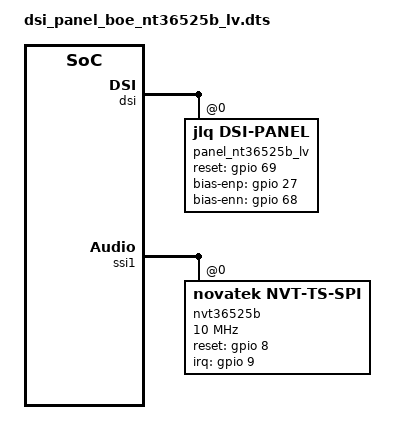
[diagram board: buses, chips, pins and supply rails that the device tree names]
// SPDX-License-Identifier: GPL-2.0+
/dts-v1/;
/plugin/;
#include <dt-bindings/pinctrl/jlq_pinctrl.h>
/ {
	jlq,panel-id   = <2 0>;
};

&dsi {
	panel_nt36525b_lv: nt36525b_lv {
		compatible = "jlq,dsi-panel";
		reg = <0>;
		panel_name = "xiaomi C3QP 35 02 0a hd+ video dsi panel";
		status = "okay";
		inited = "true";

		pinctrl-names = "panel_active", "panel_suspend";
		pinctrl-0 = <&lcd_reset_active
			&lcd_bias_enp_active
			&lcd_bias_enn_active>;
		pinctrl-1 = <&lcd_reset_suspend
			&lcd_bias_enp_suspend
			&lcd_bias_enn_suspend>;

		reset-gpio = <&gpio 69 0>;
		reset-sequence = <1 10 0 20 1 10>;
		reset-gpio-keep-high;
		bias-enp-gpio = <&gpio 27 0>;
		bias-enn-gpio = <&gpio 68 0>;

		dsi,lanes = <4>;
		dsi,channel = <0>;
		dsi,flags = <0x29400803>;
		dsi,format = <0>;

		init-delay-ms = <20>;
		prepare-delay-ms = <0>;
		enable-delay-ms = <2>;
		unprepare-delay-ms = <0>;
		disable-delay-ms = <2>;
		reset-delay-ms = <30>;
		width-mm = <68>;
		height-mm = <156>;
		backlight-type = <1>;
		backlight-max-level = <2047>;
		ic-vendor = <1>;
		cabc-support;
		hbm-support;
		hbm-percent = <80>;
                esd-check-mode = "reg_read";
                esd-check-period = <6000>;

		hbm-on-sequence = [
			29 01 02 ff 10
			29 00 02 fb 01
			29 00 03 51 07 d6
		];

		hbm-off-sequence = [
			29 01 02 ff 10
			29 00 02 fb 01
			29 00 03 51 06 65
		];

		mipi-pre-sequence = [
			29 01 02 ff 10
			29 00 02 fb 01
		];

		bl-off-pre-sequence = [
			29 00 02 53 24
		];

		panel-exit-sequence = [
			05 05 01 28
			05 78 01 10
		];

		panel-init-sequence = [
			//Gamma offset Related
			29 01 02 ff 20
			29 00 02 fb 01
			29 00 0d c3 27 26 1e 20 19 18 17 16 15 13 07 03

			29 01 02 ff 23
			29 00 02 fb 01
			29 00 02 00 68
			29 00 02 07 00
			29 00 02 08 01
			29 00 02 09 80

			//APL_WT = 0
			29 00 02 10 00

			//Resolution Related
			29 00 02 11 00
			29 00 02 12 90
			29 00 02 15 49
			29 00 02 16 09

			//GAMMA SEL
			29 00 02 19 00
			29 00 02 1a 00
			29 00 02 1b 08
			29 00 02 1c 0A
			29 00 02 1d 0C
			29 00 02 1e 12
			29 00 02 1f 16
			29 00 02 20 1A
			29 00 02 21 1C
			29 00 02 22 20
			29 00 02 23 24
			29 00 02 24 28
			29 00 02 25 2C
			29 00 02 26 30
			29 00 02 27 38
			29 00 02 28 3C
			29 00 02 29 10
			29 00 02 2a 20
			29 00 02 2b 20

			//PWM Related : UI Mode
			29 00 02 30 ff
			29 00 02 31 fe
			29 00 02 32 fd
			29 00 02 33 fc
			29 00 02 34 fb
			29 00 02 35 fa
			29 00 02 36 f9
			29 00 02 37 f8
			29 00 02 38 f7
			29 00 02 39 f6
			29 00 02 3a f5
			29 00 02 3b f4
			29 00 02 3d f3
			29 00 02 3f f2
			29 00 02 40 f1
			29 00 02 41 f0

			//PWM Related : Still Mode
			29 00 02 45 fe
			29 00 02 46 fe
			29 00 02 47 fd
			29 00 02 48 fb
			29 00 02 49 f9
			29 00 02 4a f6
			29 00 02 4b f2
			29 00 02 4c ed
			29 00 02 4d e7
			29 00 02 4e e0
			29 00 02 4f d8
			29 00 02 50 ce
			29 00 02 51 c2
			29 00 02 52 b4
			29 00 02 53 a4
			29 00 02 54 94

			//PWM Related : Mov Mode
			29 00 02 58 ff
			29 00 02 59 fe
			29 00 02 5a fc
			29 00 02 5b f9
			29 00 02 5c f5
			29 00 02 5d f1
			29 00 02 5e ed
			29 00 02 5f e8
			29 00 02 60 e2
			29 00 02 61 dc
			29 00 02 62 d6
			29 00 02 63 cf
			29 00 02 64 c7
			29 00 02 65 be
			29 00 02 66 ae
			29 00 02 67 9e

			29 01 02 ff 10
			29 00 02 fb 01
			29 00 02 51 00
			29 00 02 53 2c
			29 00 02 55 01
			29 00 03 68 03 01
			29 00 02 ba 03
			05 64 01 11
			05 32 01 29
		];

		lockdown-entries {
			#address-cells = <1>;
			#size-cells = <0>;

			lockdown-entry@0 {
				reg = <0>;
				return-packet-size = <1>;
				read-sequence = [
					29 01 02 ff 25
					29 01 02 fb 01
					06 01 01 d9
				];
			};

			lockdown-entry@1 {
				reg = <1>;
				return-packet-size = <1>;
				read-sequence = [
					29 01 02 ff 25
					29 01 02 fb 01
					06 01 01 da
				];
			};

			lockdown-entry@2 {
				reg = <2>;
				return-packet-size = <1>;
				read-sequence = [
					29 01 02 ff 25
					29 01 02 fb 01
					06 01 01 db
				];
			};

			lockdown-entry@3 {
				reg = <3>;
				return-packet-size = <1>;
				read-sequence = [
					29 01 02 ff 25
					29 01 02 fb 01
					06 01 01 dc
				];
			};

			lockdown-entry@4 {
				reg = <4>;
				return-packet-size = <1>;
				read-sequence = [
					29 01 02 ff 25
					29 01 02 fb 01
					06 01 01 dd
				];
			};

			lockdown-entry@5 {
				reg = <5>;
				return-packet-size = <1>;
				read-sequence = [
					29 01 02 ff 25
					29 01 02 fb 01
					06 01 01 f0
				];
			};

			lockdown-entry@6 {
				reg = <6>;
				return-packet-size = <1>;
				read-sequence = [
					29 01 02 ff 25
					29 01 02 fb 01
					06 01 01 f1
				];
			};

			lockdown-entry@7 {
				reg = <7>;
				return-packet-size = <1>;
				read-sequence = [
					29 01 02 ff 25
					29 01 02 fb 01
					06 01 01 f2
				];
			};
		};

		whitepoint-entries {
			#address-cells = <1>;
			#size-cells = <0>;

			whitepoint-entry@0 {
				reg = <0>;
				return-packet-size = <1>;
				read-sequence = [
					29 01 02 ff 20
					29 01 02 fb 01
					06 01 01 23
				];
			};

			whitepoint-entry@1 {
				reg = <1>;
				return-packet-size = <1>;
				read-sequence = [
					29 01 02 ff 20
					29 01 02 fb 01
					06 01 01 24
				];
			};

			whitepoint-entry@2 {
				reg = <2>;
				return-packet-size = <1>;
				read-sequence = [
					29 01 02 ff 20
					29 01 02 fb 01
					06 01 01 25
				];
			};

			whitepoint-entry@3 {
				reg = <3>;
				return-packet-size = <1>;
				read-sequence = [
					29 01 02 ff 20
					29 01 02 fb 01
					06 01 01 26
				];
			};

			whitepoint-entry@4 {
				reg = <4>;
				return-packet-size = <1>;
				read-sequence = [
					29 01 02 ff 20
					29 01 02 fb 01
					06 01 01 27
				];
			};

			whitepoint-entry@5 {
				reg = <5>;
				return-packet-size = <1>;
				read-sequence = [
					29 01 02 ff 20
					29 01 02 fb 01
					06 01 01 28
				];
			};
		};

                esd-entries {
                       #address-cells = <1>;
                       #size-cells = <0>;

                       esd-entry@0 {
                               reg = <0>;
                               return-packet-size = <1>;
                               valid-value-array = /bits/ 8 <0x9c>;
                               read-sequence = [
                                       29 01 02 ff 10
                                       29 00 02 fb 01
                                       06 01 01 0a
                               ];
                       };
               };


		display-timings {
			native-mode = <&nt36525b_lv_timing>;
			nt36525b_lv_timing: timing0 {
				clock-frequency = <110000000>;
				hactive = <720>;
				vactive = <1650>;
				hfront-porch = <120>;
				hsync-len = <2>;
				hback-porch = <108>;
				vfront-porch = <16>;
				vsync-len = <18>;
				vback-porch = <252>;
				hsync-active = <1>;
				vsync-active = <1>;
			};
		};
	};
};

&ssi1 {
	nvt36525b@0 {
		reg = <0>;
		status = "okay";
		panel = <&panel_nt36525b_lv>;
		compatible = "novatek,NVT-ts-spi";
		novatek,reset-gpio = <&gpio 8 0>;
		novatek,irq-gpio = <&gpio 9 0>;
		novatek,longv-mode = <0x1>;
		novatek,swrst-n8-addr = <0x03F0FE>;
		novatek,spi-rd-fast-addr = <0x03F310>;
		novatek,resolution-width = /bits/ 16 <720>;
		novatek,resolution-height = /bits/ 16 <1650>;
		spi-max-frequency = <10000000>;
                usb-dev-extcons = "4-006b", "4-003b";

		/* MP */
		novatek,mp-support-dt;
		novatek-mp-criteria-5968@0 {
			#address-cells = <1>;
			#size-cells = <0>;
			compatible = "novatek-mp-criteria-5968";

			/* MP Config */
			IC_X_CFG_SIZE = <18>;
			IC_Y_CFG_SIZE = <32>;
			IC_KEY_CFG_SIZE = <4>;
			X_Channel = <18>;
			Y_Channel = <32>;
			AIN_X = <0 1 2 3 4 5 6 7 8 9 10 11 12 13 14 15 16 17>;
			AIN_Y = <0 1 2 3 4 5 6 7 8 9 10 11 12 13 14 15 16 17 18 19 20 21 22 23 24 25 26 27 28 29 30 31>;
			//AIN_X = <0 1 2 3 4 5 6 7 8 9 10 11 12 13 14 15 16 17 18 19 20 21 22 23 24 25 26 27 28 29 30 31>;
			//AIN_Y = <0 1 2 3 4 5 6 7 8 9 10 11 12 13 14 15 16 17 18 19 20 21 22 23 24 25 26 27 28 29 30 31 32 33 34 35 36 37 38 39 40 41 42 43 44 45 46 47 48 49>;
			AIN_KEY = <0 1 2 0xFF>;

			/* MP Criteria */
			PS_Config_Lmt_Short_Rawdata_P = <
				14008	14008	14008	14008	14008	14008	14008	14008	14008	14008	14008	14008	14008	14008	14008	14008	14008	14008
				14008	14008	14008	14008	14008	14008	14008	14008	14008	14008	14008	14008	14008	14008	14008	14008	14008	14008
				14008	14008	14008	14008	14008	14008	14008	14008	14008	14008	14008	14008	14008	14008	14008	14008	14008	14008
				14008	14008	14008	14008	14008	14008	14008	14008	14008	14008	14008	14008	14008	14008	14008	14008	14008	14008
				14008	14008	14008	14008	14008	14008	14008	14008	14008	14008	14008	14008	14008	14008	14008	14008	14008	14008
				14008	14008	14008	14008	14008	14008	14008	14008	14008	14008	14008	14008	14008	14008	14008	14008	14008	14008
				14008	14008	14008	14008	14008	14008	14008	14008	14008	14008	14008	14008	14008	14008	14008	14008	14008	14008
				14008	14008	14008	14008	14008	14008	14008	14008	14008	14008	14008	14008	14008	14008	14008	14008	14008	14008
				14008	14008	14008	14008	14008	14008	14008	14008	14008	14008	14008	14008	14008	14008	14008	14008	14008	14008
				14008	14008	14008	14008	14008	14008	14008	14008	14008	14008	14008	14008	14008	14008	14008	14008	14008	14008
				14008	14008	14008	14008	14008	14008	14008	14008	14008	14008	14008	14008	14008	14008	14008	14008	14008	14008
				14008	14008	14008	14008	14008	14008	14008	14008	14008	14008	14008	14008	14008	14008	14008	14008	14008	14008
				14008	14008	14008	14008	14008	14008	14008	14008	14008	14008	14008	14008	14008	14008	14008	14008	14008	14008
				14008	14008	14008	14008	14008	14008	14008	14008	14008	14008	14008	14008	14008	14008	14008	14008	14008	14008
				14008	14008	14008	14008	14008	14008	14008	14008	14008	14008	14008	14008	14008	14008	14008	14008	14008	14008
				14008	14008	14008	14008	14008	14008	14008	14008	14008	14008	14008	14008	14008	14008	14008	14008	14008	14008
				14008	14008	14008	14008	14008	14008	14008	14008	14008	14008	14008	14008	14008	14008	14008	14008	14008	14008
				14008	14008	14008	14008	14008	14008	14008	14008	14008	14008	14008	14008	14008	14008	14008	14008	14008	14008
				14008	14008	14008	14008	14008	14008	14008	14008	14008	14008	14008	14008	14008	14008	14008	14008	14008	14008
				14008	14008	14008	14008	14008	14008	14008	14008	14008	14008	14008	14008	14008	14008	14008	14008	14008	14008
				14008	14008	14008	14008	14008	14008	14008	14008	14008	14008	14008	14008	14008	14008	14008	14008	14008	14008
				14008	14008	14008	14008	14008	14008	14008	14008	14008	14008	14008	14008	14008	14008	14008	14008	14008	14008
				14008	14008	14008	14008	14008	14008	14008	14008	14008	14008	14008	14008	14008	14008	14008	14008	14008	14008
				14008	14008	14008	14008	14008	14008	14008	14008	14008	14008	14008	14008	14008	14008	14008	14008	14008	14008
				14008	14008	14008	14008	14008	14008	14008	14008	14008	14008	14008	14008	14008	14008	14008	14008	14008	14008
				14008	14008	14008	14008	14008	14008	14008	14008	14008	14008	14008	14008	14008	14008	14008	14008	14008	14008
				14008	14008	14008	14008	14008	14008	14008	14008	14008	14008	14008	14008	14008	14008	14008	14008	14008	14008
				14008	14008	14008	14008	14008	14008	14008	14008	14008	14008	14008	14008	14008	14008	14008	14008	14008	14008
				14008	14008	14008	14008	14008	14008	14008	14008	14008	14008	14008	14008	14008	14008	14008	14008	14008	14008
				14008	14008	14008	14008	14008	14008	14008	14008	14008	14008	14008	14008	14008	14008	14008	14008	14008	14008
				14008	14008	14008	14008	14008	14008	14008	14008	14008	14008	14008	14008	14008	14008	14008	14008	14008	14008
				14008	14008	14008	14008	14008	14008	14008	14008	14008	14008	14008	14008	14008	14008	14008	14008	14008	14008>;

			PS_Config_Lmt_Short_Rawdata_N = <
				11376	11376	11376	11376	11376	11376	11376	11376	11376	11376	11376	11376	11376	11376	11376	11376	11376	11376
				11376	11376	11376	11376	11376	11376	11376	11376	11376	11376	11376	11376	11376	11376	11376	11376	11376	11376
				11376	11376	11376	11376	11376	11376	11376	11376	11376	11376	11376	11376	11376	11376	11376	11376	11376	11376
				11376	11376	11376	11376	11376	11376	11376	11376	11376	11376	11376	11376	11376	11376	11376	11376	11376	11376
				11376	11376	11376	11376	11376	11376	11376	11376	11376	11376	11376	11376	11376	11376	11376	11376	11376	11376
				11376	11376	11376	11376	11376	11376	11376	11376	11376	11376	11376	11376	11376	11376	11376	11376	11376	11376
				11376	11376	11376	11376	11376	11376	11376	11376	11376	11376	11376	11376	11376	11376	11376	11376	11376	11376
				11376	11376	11376	11376	11376	11376	11376	11376	11376	11376	11376	11376	11376	11376	11376	11376	11376	11376
				11376	11376	11376	11376	11376	11376	11376	11376	11376	11376	11376	11376	11376	11376	11376	11376	11376	11376
				11376	11376	11376	11376	11376	11376	11376	11376	11376	11376	11376	11376	11376	11376	11376	11376	11376	11376
				11376	11376	11376	11376	11376	11376	11376	11376	11376	11376	11376	11376	11376	11376	11376	11376	11376	11376
				11376	11376	11376	11376	11376	11376	11376	11376	11376	11376	11376	11376	11376	11376	11376	11376	11376	11376
				11376	11376	11376	11376	11376	11376	11376	11376	11376	11376	11376	11376	11376	11376	11376	11376	11376	11376
				11376	11376	11376	11376	11376	11376	11376	11376	11376	11376	11376	11376	11376	11376	11376	11376	11376	11376
				11376	11376	11376	11376	11376	11376	11376	11376	11376	11376	11376	11376	11376	11376	11376	11376	11376	11376
				11376	11376	11376	11376	11376	11376	11376	11376	11376	11376	11376	11376	11376	11376	11376	11376	11376	11376
				11376	11376	11376	11376	11376	11376	11376	11376	11376	11376	11376	11376	11376	11376	11376	11376	11376	11376
				11376	11376	11376	11376	11376	11376	11376	11376	11376	11376	11376	11376	11376	11376	11376	11376	11376	11376
				11376	11376	11376	11376	11376	11376	11376	11376	11376	11376	11376	11376	11376	11376	11376	11376	11376	11376
				11376	11376	11376	11376	11376	11376	11376	11376	11376	11376	11376	11376	11376	11376	11376	11376	11376	11376
				11376	11376	11376	11376	11376	11376	11376	11376	11376	11376	11376	11376	11376	11376	11376	11376	11376	11376
				11376	11376	11376	11376	11376	11376	11376	11376	11376	11376	11376	11376	11376	11376	11376	11376	11376	11376
				11376	11376	11376	11376	11376	11376	11376	11376	11376	11376	11376	11376	11376	11376	11376	11376	11376	11376
				11376	11376	11376	11376	11376	11376	11376	11376	11376	11376	11376	11376	11376	11376	11376	11376	11376	11376
				11376	11376	11376	11376	11376	11376	11376	11376	11376	11376	11376	11376	11376	11376	11376	11376	11376	11376
				11376	11376	11376	11376	11376	11376	11376	11376	11376	11376	11376	11376	11376	11376	11376	11376	11376	11376
				11376	11376	11376	11376	11376	11376	11376	11376	11376	11376	11376	11376	11376	11376	11376	11376	11376	11376
				11376	11376	11376	11376	11376	11376	11376	11376	11376	11376	11376	11376	11376	11376	11376	11376	11376	11376
				11376	11376	11376	11376	11376	11376	11376	11376	11376	11376	11376	11376	11376	11376	11376	11376	11376	11376
				11376	11376	11376	11376	11376	11376	11376	11376	11376	11376	11376	11376	11376	11376	11376	11376	11376	11376
				11376	11376	11376	11376	11376	11376	11376	11376	11376	11376	11376	11376	11376	11376	11376	11376	11376	11376
				11376	11376	11376	11376	11376	11376	11376	11376	11376	11376	11376	11376	11376	11376	11376	11376	11376	11376>;

			PS_Config_Lmt_Open_Rawdata_P = <
				3376	3326	3341	3410	3444	3432	3330	3455	65535	65535	3379	3256	3364	3376	3395	3382	3381	3406
				3133	3151	3185	3232	3273	3274	3264	3257	3232	3213	3256	3260	3280	3280	3294	3301	3277	3225
				3187	3207	3238	3288	3333	3334	3322	3319	3283	3186	3229	3236	3250	3253	3263	3274	3253	3213
				3164	3175	3207	3257	3304	3306	3292	3290	3252	3232	3281	3288	3302	3305	3313	3326	3309	3276
				3287	3306	3340	3395	3449	3449	3434	3434	3390	3281	3334	3341	3355	3362	3369	3381	3361	3325
				3276	3290	3325	3382	3432	3446	3432	3428	3385	3333	3390	3399	3413	3420	3425	3435	3424	3390
				3339	3357	3381	3395	3397	3396	3404	3400	3365	3466	3483	3493	3484	3476	3416	3344	3297	3257
				3421	3437	3463	3479	3476	3477	3477	3473	3437	3504	3519	3526	3526	3522	3472	3400	3353	3312
				3383	3402	3428	3449	3446	3448	3444	3446	3409	3498	3516	3521	3526	3526	3476	3403	3361	3318
				3431	3448	3480	3495	3495	3497	3491	3484	3448	3554	3575	3586	3591	3593	3544	3473	3430	3386
				3493	3511	3544	3564	3558	3557	3556	3543	3519	3556	3571	3588	3593	3598	3558	3491	3449	3406
				3536	3553	3586	3605	3602	3600	3586	3577	3557	3607	3621	3635	3654	3658	3617	3547	3505	3458
				3518	3535	3585	3599	3598	3592	3581	3574	3564	3610	3624	3631	3652	3658	3623	3560	3505	3456
				3563	3579	3630	3645	3637	3638	3623	3616	3605	3651	3665	3672	3693	3697	3668	3606	3549	3504
				3567	3586	3635	3645	3641	3637	3628	3626	3612	3630	3645	3654	3665	3672	3645	3599	3547	3502
				3599	3619	3663	3672	3663	3663	3651	3647	3630	3686	3701	3711	3725	3732	3715	3672	3616	3574
				3624	3641	3683	3689	3687	3682	3675	3668	3655	3696	3708	3722	3732	3740	3722	3686	3634	3589
				3673	3690	3731	3739	3735	3732	3721	3714	3697	3746	3763	3778	3789	3799	3787	3754	3707	3662
				3679	3691	3721	3728	3728	3722	3715	3704	3690	3722	3745	3756	3770	3780	3767	3735	3700	3654
				3742	3743	3775	3789	3787	3784	3778	3764	3747	3768	3788	3803	3817	3827	3826	3789	3752	3712
				3750	3747	3781	3794	3791	3785	3778	3768	3752	3747	3771	3785	3801	3809	3810	3777	3742	3705
				3785	3781	3813	3824	3820	3817	3810	3798	3781	3788	3812	3829	3844	3854	3861	3831	3795	3763
				3824	3822	3841	3866	3866	3861	3855	3845	3823	3795	3823	3837	3854	3865	3878	3868	3844	3817
				3810	3803	3820	3844	3844	3840	3830	3819	3801	3820	3843	3859	3876	3885	3900	3894	3873	3848
				3854	3840	3858	3878	3883	3878	3872	3859	3841	3795	3823	3837	3851	3862	3876	3876	3859	3841
				3831	3817	3833	3848	3854	3848	3841	3830	3812	3862	3886	3901	3915	3929	3941	3948	3932	3917
				3768	3875	3886	3901	3903	3901	3900	3889	3873	3848	3871	3885	3890	3906	3917	3925	3915	3781
				3624	3851	3859	3869	3872	3868	3866	3858	3841	3893	3914	3929	3938	3950	3964	3977	3970	3704
				3680	3785	3787	3791	3791	3788	3782	3773	3757	3739	3760	3771	3782	3796	3812	3827	3830	3696
				3518	3752	3750	3752	3752	3743	3739	3731	3717	3749	3767	3781	3791	3805	3819	3840	3843	3572
				3578	3819	3815	3813	3813	3806	3803	3794	3781	3736	3754	3767	3775	3789	3805	3826	3836	3567
				3626	3745	3795	3792	3792	3782	3778	3766	3746	3791	3815	3829	3840	3852	3868	3887	3840	3696>;

			PS_Config_Lmt_Open_Rawdata_N = <
				1447	1425	1432	1461	1476	1471	1427	1480	(-65535)	(-65535)	1448	1395	1441	1447	1455	1449	1449	1459
				1342	1350	1365	1385	1402	1403	1399	1396	1385	1377	1395	1397	1405	1405	1411	1414	1404	1382
				1366	1374	1387	1409	1428	1429	1423	1422	1407	1365	1384	1387	1393	1394	1398	1403	1394	1377
				1356	1360	1374	1396	1416	1417	1411	1410	1393	1385	1406	1409	1415	1416	1420	1425	1418	1404
				1408	1417	1431	1455	1478	1478	1471	1471	1453	1406	1429	1432	1438	1441	1444	1449	1440	1425
				1404	1410	1425	1449	1471	1477	1471	1469	1450	1428	1453	1456	1462	1465	1468	1472	1467	1453
				1431	1438	1449	1455	1456	1455	1459	1457	1442	1485	1492	1497	1493	1489	1464	1433	1413	1396
				1466	1473	1484	1491	1489	1490	1490	1488	1473	1501	1508	1511	1511	1509	1488	1457	1437	1419
				1450	1458	1469	1478	1477	1477	1476	1477	1461	1499	1507	1509	1511	1511	1489	1458	1440	1422
				1470	1477	1491	1498	1498	1498	1496	1493	1477	1523	1532	1537	1539	1540	1519	1488	1470	1451
				1497	1504	1519	1527	1525	1524	1524	1518	1508	1524	1530	1537	1540	1542	1525	1496	1478	1459
				1515	1522	1537	1545	1543	1543	1537	1533	1524	1546	1552	1558	1566	1567	1550	1520	1502	1482
				1507	1515	1536	1542	1542	1539	1534	1531	1527	1547	1553	1556	1565	1567	1552	1525	1502	1481
				1527	1534	1555	1562	1558	1559	1552	1549	1545	1564	1570	1573	1582	1584	1572	1545	1521	1501
				1528	1537	1558	1562	1560	1558	1555	1554	1548	1555	1562	1566	1570	1573	1562	1542	1520	1501
				1542	1551	1570	1573	1570	1570	1564	1563	1555	1579	1586	1590	1596	1599	1592	1573	1549	1531
				1553	1560	1578	1581	1580	1578	1575	1572	1566	1584	1589	1595	1599	1603	1595	1579	1557	1538
				1574	1581	1599	1602	1600	1599	1594	1591	1584	1605	1612	1619	1624	1628	1623	1609	1588	1569
				1576	1582	1594	1597	1597	1595	1592	1587	1581	1595	1605	1609	1615	1620	1614	1600	1585	1566
				1603	1604	1618	1624	1623	1621	1619	1613	1606	1615	1623	1630	1636	1640	1639	1624	1608	1591
				1607	1606	1620	1626	1624	1622	1619	1615	1608	1606	1616	1622	1629	1632	1633	1618	1603	1588
				1622	1620	1634	1639	1637	1636	1633	1627	1620	1623	1633	1641	1647	1651	1654	1642	1626	1612
				1639	1638	1646	1657	1657	1654	1652	1648	1638	1626	1638	1644	1651	1656	1662	1657	1647	1636
				1633	1630	1637	1647	1647	1645	1641	1636	1629	1637	1647	1654	1661	1665	1671	1669	1660	1649
				1651	1645	1653	1662	1664	1662	1659	1654	1646	1626	1638	1644	1650	1655	1661	1661	1654	1646
				1642	1636	1642	1649	1651	1649	1646	1641	1633	1655	1665	1672	1678	1684	1689	1692	1685	1678
				1615	1660	1665	1672	1672	1672	1671	1666	1660	1649	1659	1665	1667	1674	1678	1682	1678	1620
				1553	1650	1654	1658	1659	1657	1657	1653	1646	1668	1677	1684	1687	1693	1699	1704	1701	1587
				1577	1622	1623	1624	1624	1623	1621	1617	1610	1602	1611	1616	1621	1627	1633	1640	1641	1584
				1507	1608	1607	1608	1608	1604	1602	1599	1593	1606	1614	1620	1624	1630	1636	1645	1647	1531
				1533	1636	1635	1634	1634	1631	1630	1626	1620	1601	1609	1614	1618	1624	1630	1639	1644	1528
				1554	1605	1626	1625	1625	1621	1619	1614	1605	1624	1635	1641	1645	1651	1657	1666	1645	1584>;

			PS_Config_Lmt_FW_Rawdata_P = <
				2262	2228	2235	2217	2231	2233	2248	2242	65535	65535	2262	2252	2242	2226	2240	2231	2237	2244
				2238	2249	2266	2254	2259	2251	2252	2228	2245	2196	2227	2228	2241	2228	2226	2240	2238	2240
				2261	2244	2235	2251	2235	2240	2219	2238	2234	2247	2252	2262	2263	2255	2247	2268	2242	2220
				2249	2228	2237	2217	2233	2228	2233	2244	2241	2249	2214	2221	2221	2209	2209	2213	2255	2254
				2255	2242	2231	2237	2247	2258	2245	2254	2247	2263	2258	2258	2256	2227	2238	2245	2219	2265
				2261	2233	2231	2249	2231	2234	2242	2248	2247	2245	2256	2245	2238	2258	2244	2258	2248	2217
				2249	2245	2235	2234	2242	2265	2219	2235	2227	2256	2221	2237	2221	2265	2242	2226	2247	2249
				2251	2240	2263	2242	2240	2233	2238	2248	2241	2228	2254	2251	2228	2226	2242	2255	2240	2238
				2227	2233	2262	2226	2251	2235	2234	2235	2251	2219	2213	2245	2235	2221	2268	2244	2258	2256
				2248	2245	2223	2224	2224	2241	2224	2234	2231	2235	2233	2234	2228	2200	2252	2263	2242	2235
				2227	2242	2240	2241	2247	2248	2240	2221	2235	2251	2242	2235	2235	2219	2242	2248	2258	2245
				2265	2256	2251	2248	2251	2255	2268	2259	2254	2214	2255	2262	2258	2235	2219	2241	2223	2248
				2230	2259	2247	2256	2249	2251	2249	2256	2242	2265	2228	2242	2242	2248	2259	2235	2230	2245
				2206	2272	2254	2251	2252	2249	2259	2261	2263	2234	2275	2262	2268	2240	2230	2227	2245	2242
				2248	2231	2224	2220	2249	2252	2266	2234	2244	2255	2230	2240	2244	2244	2255	2227	2234	2237
				2221	2255	2259	2251	2249	2252	2255	2251	2235	2252	2227	2224	2226	2242	2252	2244	2224	2235
				2221	2238	2256	2237	2252	2240	2241	2210	2219	2210	2231	2235	2241	2224	2219	2259	2230	2247
				2263	2207	2203	2216	2230	2265	2249	2230	2234	2240	2233	2241	2237	2249	2242	2261	2244	2241
				2212	2217	2207	2216	2200	2198	2207	2223	2212	2224	2273	2248	2214	2269	2266	2219	2249	2244
				2234	2284	2258	2276	2252	2247	2261	2235	2258	2237	2268	2248	2251	2263	2270	2261	2233	2221
				2249	2247	2241	2269	2231	2227	2249	2235	2235	2270	2224	2230	2238	2254	2240	2238	2231	2251
				2251	2248	2240	2240	2259	2251	2252	2249	2252	2210	2227	2220	2230	2217	2223	2216	2234	2251
				2245	2259	2251	2259	2234	2247	2262	2238	2238	2224	2231	2235	2242	2214	2235	2226	2254	2221
				2254	2244	2235	2242	2234	2247	2249	2259	2240	2237	2234	2227	2238	2251	2221	2233	2247	2261
				2216	2251	2242	2249	2251	2228	2247	2252	2256	2248	2249	2249	2244	2268	2256	2251	2255	2265
				2233	2248	2224	2234	2223	2228	2226	2233	2228	2251	2217	2227	2220	2244	2251	2255	2240	2224
				2254	2251	2234	2240	2266	2254	2258	2255	2233	2262	2212	2217	2221	2220	2214	2228	2226	2258
				2254	2261	2279	2263	2268	2265	2265	2263	2258	2269	2210	2209	2220	2262	2256	2220	2228	2255
				2263	2223	2224	2235	2231	2248	2231	2228	2249	2254	2227	2249	2248	2254	2248	2256	2231	2227
				2244	2247	2230	2235	2214	2212	2213	2224	2226	2231	2214	2226	2230	2272	2220	2210	2226	2252
				2259	2231	2251	2242	2251	2251	2254	2237	2254	2233	2248	2254	2262	2255	2269	2273	2234	2233
				2228	2259	2238	2220	2226	2221	2228	2227	2245	2216	2206	2202	2205	2241	2240	2235	2252	2279>;

			PS_Config_Lmt_FW_Rawdata_N = <
				969	955	958	950	956	957	963	961	(-65535)	(-65535)	969	965	961	954	960	956	958	961
				959	964	971	966	968	964	965	955	962	941	954	955	960	955	954	960	959	960
				969	961	958	964	958	960	951	959	957	963	965	969	970	966	963	972	961	951
				964	955	958	950	957	955	957	961	960	964	949	952	952	946	946	948	966	966
				966	961	956	958	963	967	962	966	963	970	967	967	967	954	959	962	951	970
				969	957	956	964	956	957	961	963	963	962	967	962	959	967	961	967	963	950
				964	962	958	957	961	970	951	958	954	967	952	958	952	970	961	954	963	964
				964	960	970	961	960	957	959	963	960	955	966	964	955	954	961	966	960	959
				954	957	969	954	964	958	957	958	964	951	948	962	958	952	972	961	967	967
				963	962	952	953	953	960	953	957	956	958	957	957	955	943	965	970	961	958
				954	961	960	960	963	963	960	952	958	964	961	958	958	951	961	963	967	962
				970	967	964	963	964	966	972	968	966	949	966	969	967	958	951	960	952	963
				955	968	963	967	964	964	964	967	961	970	955	961	961	963	968	958	955	962
				945	973	966	964	965	964	968	969	970	957	975	969	972	960	955	954	962	961
				963	956	953	951	964	965	971	957	961	966	955	960	961	961	966	954	957	958
				952	966	968	964	964	965	966	964	958	965	954	953	954	961	965	961	953	958
				952	959	967	958	965	960	960	947	951	947	956	958	960	953	951	968	955	963
				970	946	944	949	955	970	964	955	957	960	957	960	958	964	961	969	961	960
				948	950	946	949	943	942	946	952	948	953	974	963	949	972	971	951	964	961
				957	979	967	975	965	963	969	958	967	958	972	963	964	970	973	969	957	952
				964	963	960	972	956	954	964	958	958	973	953	955	959	966	960	959	956	964
				964	963	960	960	968	964	965	964	965	947	954	951	955	950	952	949	957	964
				962	968	964	968	957	963	969	959	959	953	956	958	961	949	958	954	966	952
				966	961	958	961	957	963	964	968	960	958	957	954	959	964	952	957	963	969
				949	964	961	964	964	955	963	965	967	963	964	964	961	972	967	964	966	970
				957	963	953	957	952	955	954	957	955	964	950	954	951	961	964	966	960	953
				966	964	957	960	971	966	967	966	957	969	948	950	952	951	949	955	954	967
				966	969	976	970	972	970	970	970	967	972	947	946	951	969	967	951	955	966
				970	952	953	958	956	963	956	955	964	966	954	964	963	966	963	967	956	954
				961	963	955	958	949	948	948	953	954	956	949	954	955	973	951	947	954	965
				968	956	964	961	964	964	966	958	966	957	963	966	969	966	972	974	957	957
				955	968	959	951	954	952	955	954	962	949	945	943	945	960	960	958	965	976>;

			PS_Config_Lmt_FW_CC_P = <
				91	91	91	92	92	92	92	92	65535	65535	96	96	96	95	95	95	93	95
				95	93	93	93	93	93	93	93	96	99	96	96	96	96	96	96	97	99
				95	93	93	93	93	93	93	93	96	99	97	96	97	96	96	97	97	99
				95	93	92	93	93	93	93	95	96	99	97	97	97	97	97	97	97	99
				96	95	93	95	95	95	95	95	97	99	96	96	97	96	96	97	97	99
				96	95	95	95	96	96	96	96	99	100	99	99	99	97	97	99	99	100
				96	95	95	95	95	93	95	95	97	103	100	100	100	99	99	99	99	100
				100	99	99	99	99	99	99	99	102	106	103	103	103	103	102	102	102	103
				97	96	95	95	95	95	95	95	97	103	100	100	100	100	99	99	99	100
				102	99	99	99	99	99	99	99	102	106	104	104	104	104	103	102	103	104
				97	96	95	95	95	95	95	96	97	102	100	100	100	99	99	99	99	100
				100	99	99	99	99	99	99	99	102	106	104	104	104	103	103	103	103	104
				97	96	96	96	96	95	96	96	99	103	100	100	100	100	100	99	99	102
				103	102	102	102	102	102	102	102	104	107	104	104	104	104	104	103	104	106
				97	96	96	96	96	96	96	96	99	103	102	102	102	102	100	100	100	102
				102	100	100	100	100	100	100	100	103	107	104	104	106	104	104	104	104	106
				99	96	96	96	96	96	96	96	99	104	102	102	102	102	102	100	102	103
				103	102	102	102	102	100	100	102	104	107	104	104	104	104	104	103	104	106
				99	97	96	97	96	96	96	96	99	103	102	102	102	100	100	100	102	103
				104	102	102	102	102	102	102	102	104	107	106	106	106	104	104	104	104	107
				100	97	97	97	97	97	97	97	100	103	102	102	102	102	102	102	102	103
				103	102	102	102	102	102	102	102	104	109	106	106	106	106	106	106	106	109
				100	97	97	97	97	97	97	97	100	104	102	102	102	102	102	102	102	104
				100	99	97	99	97	97	97	99	100	104	102	102	102	102	102	102	103	104
				100	97	97	97	97	97	97	97	100	106	103	103	103	103	103	103	103	106
				102	100	100	100	100	100	100	100	103	104	103	103	103	102	102	102	103	106
				100	99	99	99	99	99	99	99	102	104	103	103	103	103	103	103	103	104
				100	100	99	100	99	99	99	100	102	106	103	103	103	103	103	103	104	104
				99	99	97	97	97	97	97	97	100	104	103	103	103	102	103	103	103	104
				99	99	99	99	99	99	99	99	102	103	102	102	102	100	102	102	102	102
				97	97	97	97	97	97	97	97	100	103	100	100	100	100	100	100	102	102
				100	99	99	99	99	99	99	99	102	106	102	103	103	102	102	102	103	103>;

			PS_Config_Lmt_FW_CC_N = <
				40	40	40	41	41	41	41	41	(-65535)	(-65535)	43	43	43	42	42	42	42	42
				42	42	42	42	42	42	42	42	43	44	43	43	43	43	43	43	44	44
				42	42	42	42	42	42	42	42	43	44	44	43	44	43	43	44	44	44
				42	42	41	42	42	42	42	42	43	44	44	44	44	44	44	44	44	44
				43	42	42	42	42	42	42	42	44	44	43	43	44	43	43	44	44	44
				43	42	42	42	43	43	43	43	44	45	44	44	44	44	44	44	44	45
				43	42	42	42	42	42	42	42	44	46	45	45	45	44	44	44	44	45
				45	44	44	44	44	44	44	44	45	47	46	46	46	46	45	45	45	46
				44	43	42	42	42	42	42	42	44	46	45	45	45	45	44	44	44	45
				45	44	44	44	44	44	44	44	45	47	47	47	47	47	46	45	46	47
				44	43	42	42	42	42	42	43	44	45	45	45	45	44	44	44	44	45
				45	44	44	44	44	44	44	44	45	47	47	47	47	46	46	46	46	47
				44	43	43	43	43	42	43	43	44	46	45	45	45	45	45	44	44	45
				46	45	45	45	45	45	45	45	47	48	47	47	47	47	47	46	47	47
				44	43	43	43	43	43	43	43	44	46	45	45	45	45	45	45	45	45
				45	45	45	45	45	45	45	45	46	48	47	47	47	47	47	47	47	47
				44	43	43	43	43	43	43	43	44	47	45	45	45	45	45	45	45	46
				46	45	45	45	45	45	45	45	47	48	47	47	47	47	47	46	47	47
				44	44	43	44	43	43	43	43	44	46	45	45	45	45	45	45	45	46
				47	45	45	45	45	45	45	45	47	48	47	47	47	47	47	47	47	48
				45	44	44	44	44	44	44	44	45	46	45	45	45	45	45	45	45	46
				46	45	45	45	45	45	45	45	47	48	47	47	47	47	47	47	47	48
				45	44	44	44	44	44	44	44	45	47	45	45	45	45	45	45	45	47
				45	44	44	44	44	44	44	44	45	47	45	45	45	45	45	45	46	47
				45	44	44	44	44	44	44	44	45	47	46	46	46	46	46	46	46	47
				45	45	45	45	45	45	45	45	46	47	46	46	46	45	45	45	46	47
				45	44	44	44	44	44	44	44	45	47	46	46	46	46	46	46	46	47
				45	45	44	45	44	44	44	45	45	47	46	46	46	46	46	46	47	47
				44	44	44	44	44	44	44	44	45	47	46	46	46	45	46	46	46	47
				44	44	44	44	44	44	44	44	45	46	45	45	45	45	45	45	45	45
				44	44	44	44	44	44	44	44	45	46	45	45	45	45	45	45	45	45
				45	44	44	44	44	44	44	44	45	47	45	46	46	45	45	45	46	46>;

			PS_Config_Lmt_FW_Diff_P = <
				50	50	50	50	50	50	50	50	65535	65535	50	50	50	50	50	50	50	50
				50	50	50	50	50	50	50	50	50	50	50	50	50	50	50	50	50	50
				50	50	50	50	50	50	50	50	50	50	50	50	50	50	50	50	50	50
				50	50	50	50	50	50	50	50	50	50	50	50	50	50	50	50	50	50
				50	50	50	50	50	50	50	50	50	50	50	50	50	50	50	50	50	50
				50	50	50	50	50	50	50	50	50	50	50	50	50	50	50	50	50	50
				50	50	50	50	50	50	50	50	50	50	50	50	50	50	50	50	50	50
				50	50	50	50	50	50	50	50	50	50	50	50	50	50	50	50	50	50
				50	50	50	50	50	50	50	50	50	50	50	50	50	50	50	50	50	50
				50	50	50	50	50	50	50	50	50	50	50	50	50	50	50	50	50	50
				50	50	50	50	50	50	50	50	50	50	50	50	50	50	50	50	50	50
				50	50	50	50	50	50	50	50	50	50	50	50	50	50	50	50	50	50
				50	50	50	50	50	50	50	50	50	50	50	50	50	50	50	50	50	50
				50	50	50	50	50	50	50	50	50	50	50	50	50	50	50	50	50	50
				50	50	50	50	50	50	50	50	50	50	50	50	50	50	50	50	50	50
				50	50	50	50	50	50	50	50	50	50	50	50	50	50	50	50	50	50
				50	50	50	50	50	50	50	50	50	50	50	50	50	50	50	50	50	50
				50	50	50	50	50	50	50	50	50	50	50	50	50	50	50	50	50	50
				50	50	50	50	50	50	50	50	50	50	50	50	50	50	50	50	50	50
				50	50	50	50	50	50	50	50	50	50	50	50	50	50	50	50	50	50
				50	50	50	50	50	50	50	50	50	50	50	50	50	50	50	50	50	50
				50	50	50	50	50	50	50	50	50	50	50	50	50	50	50	50	50	50
				50	50	50	50	50	50	50	50	50	50	50	50	50	50	50	50	50	50
				50	50	50	50	50	50	50	50	50	50	50	50	50	50	50	50	50	50
				50	50	50	50	50	50	50	50	50	50	50	50	50	50	50	50	50	50
				50	50	50	50	50	50	50	50	50	50	50	50	50	50	50	50	50	50
				50	50	50	50	50	50	50	50	50	50	50	50	50	50	50	50	50	50
				50	50	50	50	50	50	50	50	50	50	50	50	50	50	50	50	50	50
				50	50	50	50	50	50	50	50	50	50	50	50	50	50	50	50	50	50
				50	50	50	50	50	50	50	50	50	50	50	50	50	50	50	50	50	50
				50	50	50	50	50	50	50	50	50	50	50	50	50	50	50	50	50	50
				50	50	50	50	50	50	50	50	50	50	50	50	50	50	50	50	50	50>;

			PS_Config_Lmt_FW_Diff_N = <
				(-50)	(-50)	(-50)	(-50)	(-50)	(-50)	(-50)	(-50)	(-65535)	(-65535)	(-50)	(-50)	(-50)	(-50)	(-50)	(-50)	(-50)	(-50)
				(-50)	(-50)	(-50)	(-50)	(-50)	(-50)	(-50)	(-50)	(-50)	(-50)	(-50)	(-50)	(-50)	(-50)	(-50)	(-50)	(-50)	(-50)
				(-50)	(-50)	(-50)	(-50)	(-50)	(-50)	(-50)	(-50)	(-50)	(-50)	(-50)	(-50)	(-50)	(-50)	(-50)	(-50)	(-50)	(-50)
				(-50)	(-50)	(-50)	(-50)	(-50)	(-50)	(-50)	(-50)	(-50)	(-50)	(-50)	(-50)	(-50)	(-50)	(-50)	(-50)	(-50)	(-50)
				(-50)	(-50)	(-50)	(-50)	(-50)	(-50)	(-50)	(-50)	(-50)	(-50)	(-50)	(-50)	(-50)	(-50)	(-50)	(-50)	(-50)	(-50)
				(-50)	(-50)	(-50)	(-50)	(-50)	(-50)	(-50)	(-50)	(-50)	(-50)	(-50)	(-50)	(-50)	(-50)	(-50)	(-50)	(-50)	(-50)
				(-50)	(-50)	(-50)	(-50)	(-50)	(-50)	(-50)	(-50)	(-50)	(-50)	(-50)	(-50)	(-50)	(-50)	(-50)	(-50)	(-50)	(-50)
				(-50)	(-50)	(-50)	(-50)	(-50)	(-50)	(-50)	(-50)	(-50)	(-50)	(-50)	(-50)	(-50)	(-50)	(-50)	(-50)	(-50)	(-50)
				(-50)	(-50)	(-50)	(-50)	(-50)	(-50)	(-50)	(-50)	(-50)	(-50)	(-50)	(-50)	(-50)	(-50)	(-50)	(-50)	(-50)	(-50)
				(-50)	(-50)	(-50)	(-50)	(-50)	(-50)	(-50)	(-50)	(-50)	(-50)	(-50)	(-50)	(-50)	(-50)	(-50)	(-50)	(-50)	(-50)
				(-50)	(-50)	(-50)	(-50)	(-50)	(-50)	(-50)	(-50)	(-50)	(-50)	(-50)	(-50)	(-50)	(-50)	(-50)	(-50)	(-50)	(-50)
				(-50)	(-50)	(-50)	(-50)	(-50)	(-50)	(-50)	(-50)	(-50)	(-50)	(-50)	(-50)	(-50)	(-50)	(-50)	(-50)	(-50)	(-50)
				(-50)	(-50)	(-50)	(-50)	(-50)	(-50)	(-50)	(-50)	(-50)	(-50)	(-50)	(-50)	(-50)	(-50)	(-50)	(-50)	(-50)	(-50)
				(-50)	(-50)	(-50)	(-50)	(-50)	(-50)	(-50)	(-50)	(-50)	(-50)	(-50)	(-50)	(-50)	(-50)	(-50)	(-50)	(-50)	(-50)
				(-50)	(-50)	(-50)	(-50)	(-50)	(-50)	(-50)	(-50)	(-50)	(-50)	(-50)	(-50)	(-50)	(-50)	(-50)	(-50)	(-50)	(-50)
				(-50)	(-50)	(-50)	(-50)	(-50)	(-50)	(-50)	(-50)	(-50)	(-50)	(-50)	(-50)	(-50)	(-50)	(-50)	(-50)	(-50)	(-50)
				(-50)	(-50)	(-50)	(-50)	(-50)	(-50)	(-50)	(-50)	(-50)	(-50)	(-50)	(-50)	(-50)	(-50)	(-50)	(-50)	(-50)	(-50)
				(-50)	(-50)	(-50)	(-50)	(-50)	(-50)	(-50)	(-50)	(-50)	(-50)	(-50)	(-50)	(-50)	(-50)	(-50)	(-50)	(-50)	(-50)
				(-50)	(-50)	(-50)	(-50)	(-50)	(-50)	(-50)	(-50)	(-50)	(-50)	(-50)	(-50)	(-50)	(-50)	(-50)	(-50)	(-50)	(-50)
				(-50)	(-50)	(-50)	(-50)	(-50)	(-50)	(-50)	(-50)	(-50)	(-50)	(-50)	(-50)	(-50)	(-50)	(-50)	(-50)	(-50)	(-50)
				(-50)	(-50)	(-50)	(-50)	(-50)	(-50)	(-50)	(-50)	(-50)	(-50)	(-50)	(-50)	(-50)	(-50)	(-50)	(-50)	(-50)	(-50)
				(-50)	(-50)	(-50)	(-50)	(-50)	(-50)	(-50)	(-50)	(-50)	(-50)	(-50)	(-50)	(-50)	(-50)	(-50)	(-50)	(-50)	(-50)
				(-50)	(-50)	(-50)	(-50)	(-50)	(-50)	(-50)	(-50)	(-50)	(-50)	(-50)	(-50)	(-50)	(-50)	(-50)	(-50)	(-50)	(-50)
				(-50)	(-50)	(-50)	(-50)	(-50)	(-50)	(-50)	(-50)	(-50)	(-50)	(-50)	(-50)	(-50)	(-50)	(-50)	(-50)	(-50)	(-50)
				(-50)	(-50)	(-50)	(-50)	(-50)	(-50)	(-50)	(-50)	(-50)	(-50)	(-50)	(-50)	(-50)	(-50)	(-50)	(-50)	(-50)	(-50)
				(-50)	(-50)	(-50)	(-50)	(-50)	(-50)	(-50)	(-50)	(-50)	(-50)	(-50)	(-50)	(-50)	(-50)	(-50)	(-50)	(-50)	(-50)
				(-50)	(-50)	(-50)	(-50)	(-50)	(-50)	(-50)	(-50)	(-50)	(-50)	(-50)	(-50)	(-50)	(-50)	(-50)	(-50)	(-50)	(-50)
				(-50)	(-50)	(-50)	(-50)	(-50)	(-50)	(-50)	(-50)	(-50)	(-50)	(-50)	(-50)	(-50)	(-50)	(-50)	(-50)	(-50)	(-50)
				(-50)	(-50)	(-50)	(-50)	(-50)	(-50)	(-50)	(-50)	(-50)	(-50)	(-50)	(-50)	(-50)	(-50)	(-50)	(-50)	(-50)	(-50)
				(-50)	(-50)	(-50)	(-50)	(-50)	(-50)	(-50)	(-50)	(-50)	(-50)	(-50)	(-50)	(-50)	(-50)	(-50)	(-50)	(-50)	(-50)
				(-50)	(-50)	(-50)	(-50)	(-50)	(-50)	(-50)	(-50)	(-50)	(-50)	(-50)	(-50)	(-50)	(-50)	(-50)	(-50)	(-50)	(-50)
				(-50)	(-50)	(-50)	(-50)	(-50)	(-50)	(-50)	(-50)	(-50)	(-50)	(-50)	(-50)	(-50)	(-50)	(-50)	(-50)	(-50)	(-50)>;

			PS_Config_Lmt_PenTipX_FW_Raw_P = <
				570 570 570 570 570 570 570 570 570 570 570 570 570 570 570 570 570 570 570 570 570 570 570 570 570 570 570 570 570 570 570 570
				570 570 570 570 570 570 570 570 570 570 570 570 570 570 570 570 570 570 570 570 570 570 570 570 570 570 570 570 570 570 570 570
				570 570 570 570 570 570 570 570 570 570 570 570 570 570 570 570 570 570 570 570 570 570 570 570 570 570 570 570 570 570 570 570
				570 570 570 570 570 570 570 570 570 570 570 570 570 570 570 570 570 570 570 570 570 570 570 570 570 570 570 570 570 570 570 570
				570 570 570 570 570 570 570 570 570 570 570 570 570 570 570 570 570 570 570 570 570 570 570 570 570 570 570 570 570 570 570 570
				570 570 570 570 570 570 570 570 570 570 570 570 570 570 570 570 570 570 570 570 570 570 570 570 570 570 570 570 570 570 570 570>;

			PS_Config_Lmt_PenTipX_FW_Raw_N = <
				(-570) (-570) (-570) (-570) (-570) (-570) (-570) (-570) (-570) (-570) (-570) (-570) (-570) (-570) (-570) (-570) (-570) (-570) (-570) (-570) (-570) (-570) (-570) (-570) (-570) (-570) (-570) (-570) (-570) (-570) (-570) (-570)
				(-570) (-570) (-570) (-570) (-570) (-570) (-570) (-570) (-570) (-570) (-570) (-570) (-570) (-570) (-570) (-570) (-570) (-570) (-570) (-570) (-570) (-570) (-570) (-570) (-570) (-570) (-570) (-570) (-570) (-570) (-570) (-570)
				(-570) (-570) (-570) (-570) (-570) (-570) (-570) (-570) (-570) (-570) (-570) (-570) (-570) (-570) (-570) (-570) (-570) (-570) (-570) (-570) (-570) (-570) (-570) (-570) (-570) (-570) (-570) (-570) (-570) (-570) (-570) (-570)
				(-570) (-570) (-570) (-570) (-570) (-570) (-570) (-570) (-570) (-570) (-570) (-570) (-570) (-570) (-570) (-570) (-570) (-570) (-570) (-570) (-570) (-570) (-570) (-570) (-570) (-570) (-570) (-570) (-570) (-570) (-570) (-570)
				(-570) (-570) (-570) (-570) (-570) (-570) (-570) (-570) (-570) (-570) (-570) (-570) (-570) (-570) (-570) (-570) (-570) (-570) (-570) (-570) (-570) (-570) (-570) (-570) (-570) (-570) (-570) (-570) (-570) (-570) (-570) (-570)
				(-570) (-570) (-570) (-570) (-570) (-570) (-570) (-570) (-570) (-570) (-570) (-570) (-570) (-570) (-570) (-570) (-570) (-570) (-570) (-570) (-570) (-570) (-570) (-570) (-570) (-570) (-570) (-570) (-570) (-570) (-570) (-570)>;

			PS_Config_Lmt_PenTipY_FW_Raw_P = <
				570 570 570 570
				570 570 570 570
				570 570 570 570
				570 570 570 570
				570 570 570 570
				570 570 570 570
				570 570 570 570
				570 570 570 570
				570 570 570 570
				570 570 570 570
				570 570 570 570
				570 570 570 570
				570 570 570 570
				570 570 570 570
				570 570 570 570
				570 570 570 570
				570 570 570 570
				570 570 570 570
				570 570 570 570
				570 570 570 570
				570 570 570 570
				570 570 570 570
				570 570 570 570
				570 570 570 570
				570 570 570 570
				570 570 570 570
				570 570 570 570
				570 570 570 570
				570 570 570 570
				570 570 570 570
				570 570 570 570
				570 570 570 570
				570 570 570 570
				570 570 570 570
				570 570 570 570
				570 570 570 570
				570 570 570 570
				570 570 570 570
				570 570 570 570
				570 570 570 570
				570 570 570 570
				570 570 570 570
				570 570 570 570
				570 570 570 570
				570 570 570 570
				570 570 570 570
				570 570 570 570
				570 570 570 570
				570 570 570 570
				570 570 570 570>;

			PS_Config_Lmt_PenTipY_FW_Raw_N = <
				(-570) (-570) (-570) (-570)
				(-570) (-570) (-570) (-570)
				(-570) (-570) (-570) (-570)
				(-570) (-570) (-570) (-570)
				(-570) (-570) (-570) (-570)
				(-570) (-570) (-570) (-570)
				(-570) (-570) (-570) (-570)
				(-570) (-570) (-570) (-570)
				(-570) (-570) (-570) (-570)
				(-570) (-570) (-570) (-570)
				(-570) (-570) (-570) (-570)
				(-570) (-570) (-570) (-570)
				(-570) (-570) (-570) (-570)
				(-570) (-570) (-570) (-570)
				(-570) (-570) (-570) (-570)
				(-570) (-570) (-570) (-570)
				(-570) (-570) (-570) (-570)
				(-570) (-570) (-570) (-570)
				(-570) (-570) (-570) (-570)
				(-570) (-570) (-570) (-570)
				(-570) (-570) (-570) (-570)
				(-570) (-570) (-570) (-570)
				(-570) (-570) (-570) (-570)
				(-570) (-570) (-570) (-570)
				(-570) (-570) (-570) (-570)
				(-570) (-570) (-570) (-570)
				(-570) (-570) (-570) (-570)
				(-570) (-570) (-570) (-570)
				(-570) (-570) (-570) (-570)
				(-570) (-570) (-570) (-570)
				(-570) (-570) (-570) (-570)
				(-570) (-570) (-570) (-570)
				(-570) (-570) (-570) (-570)
				(-570) (-570) (-570) (-570)
				(-570) (-570) (-570) (-570)
				(-570) (-570) (-570) (-570)
				(-570) (-570) (-570) (-570)
				(-570) (-570) (-570) (-570)
				(-570) (-570) (-570) (-570)
				(-570) (-570) (-570) (-570)
				(-570) (-570) (-570) (-570)
				(-570) (-570) (-570) (-570)
				(-570) (-570) (-570) (-570)
				(-570) (-570) (-570) (-570)
				(-570) (-570) (-570) (-570)
				(-570) (-570) (-570) (-570)
				(-570) (-570) (-570) (-570)
				(-570) (-570) (-570) (-570)
				(-570) (-570) (-570) (-570)
				(-570) (-570) (-570) (-570)>;

			PS_Config_Lmt_PenRingX_FW_Raw_P = <
				570 570 570 570 570 570 570 570 570 570 570 570 570 570 570 570 570 570 570 570 570 570 570 570 570 570 570 570 570 570 570 570
				570 570 570 570 570 570 570 570 570 570 570 570 570 570 570 570 570 570 570 570 570 570 570 570 570 570 570 570 570 570 570 570
				570 570 570 570 570 570 570 570 570 570 570 570 570 570 570 570 570 570 570 570 570 570 570 570 570 570 570 570 570 570 570 570
				570 570 570 570 570 570 570 570 570 570 570 570 570 570 570 570 570 570 570 570 570 570 570 570 570 570 570 570 570 570 570 570
				570 570 570 570 570 570 570 570 570 570 570 570 570 570 570 570 570 570 570 570 570 570 570 570 570 570 570 570 570 570 570 570
				570 570 570 570 570 570 570 570 570 570 570 570 570 570 570 570 570 570 570 570 570 570 570 570 570 570 570 570 570 570 570 570>;

			PS_Config_Lmt_PenRingX_FW_Raw_N = <
				(-570) (-570) (-570) (-570) (-570) (-570) (-570) (-570) (-570) (-570) (-570) (-570) (-570) (-570) (-570) (-570) (-570) (-570) (-570) (-570) (-570) (-570) (-570) (-570) (-570) (-570) (-570) (-570) (-570) (-570) (-570) (-570)
				(-570) (-570) (-570) (-570) (-570) (-570) (-570) (-570) (-570) (-570) (-570) (-570) (-570) (-570) (-570) (-570) (-570) (-570) (-570) (-570) (-570) (-570) (-570) (-570) (-570) (-570) (-570) (-570) (-570) (-570) (-570) (-570)
				(-570) (-570) (-570) (-570) (-570) (-570) (-570) (-570) (-570) (-570) (-570) (-570) (-570) (-570) (-570) (-570) (-570) (-570) (-570) (-570) (-570) (-570) (-570) (-570) (-570) (-570) (-570) (-570) (-570) (-570) (-570) (-570)
				(-570) (-570) (-570) (-570) (-570) (-570) (-570) (-570) (-570) (-570) (-570) (-570) (-570) (-570) (-570) (-570) (-570) (-570) (-570) (-570) (-570) (-570) (-570) (-570) (-570) (-570) (-570) (-570) (-570) (-570) (-570) (-570)
				(-570) (-570) (-570) (-570) (-570) (-570) (-570) (-570) (-570) (-570) (-570) (-570) (-570) (-570) (-570) (-570) (-570) (-570) (-570) (-570) (-570) (-570) (-570) (-570) (-570) (-570) (-570) (-570) (-570) (-570) (-570) (-570)
				(-570) (-570) (-570) (-570) (-570) (-570) (-570) (-570) (-570) (-570) (-570) (-570) (-570) (-570) (-570) (-570) (-570) (-570) (-570) (-570) (-570) (-570) (-570) (-570) (-570) (-570) (-570) (-570) (-570) (-570) (-570) (-570)>;

			PS_Config_Lmt_PenRingY_FW_Raw_P = <
				570 570 570 570
				570 570 570 570
				570 570 570 570
				570 570 570 570
				570 570 570 570
				570 570 570 570
				570 570 570 570
				570 570 570 570
				570 570 570 570
				570 570 570 570
				570 570 570 570
				570 570 570 570
				570 570 570 570
				570 570 570 570
				570 570 570 570
				570 570 570 570
				570 570 570 570
				570 570 570 570
				570 570 570 570
				570 570 570 570
				570 570 570 570
				570 570 570 570
				570 570 570 570
				570 570 570 570
				570 570 570 570
				570 570 570 570
				570 570 570 570
				570 570 570 570
				570 570 570 570
				570 570 570 570
				570 570 570 570
				570 570 570 570
				570 570 570 570
				570 570 570 570
				570 570 570 570
				570 570 570 570
				570 570 570 570
				570 570 570 570
				570 570 570 570
				570 570 570 570
				570 570 570 570
				570 570 570 570
				570 570 570 570
				570 570 570 570
				570 570 570 570
				570 570 570 570
				570 570 570 570
				570 570 570 570
				570 570 570 570
				570 570 570 570>;

			PS_Config_Lmt_PenRingY_FW_Raw_N = <
				(-570) (-570) (-570) (-570)
				(-570) (-570) (-570) (-570)
				(-570) (-570) (-570) (-570)
				(-570) (-570) (-570) (-570)
				(-570) (-570) (-570) (-570)
				(-570) (-570) (-570) (-570)
				(-570) (-570) (-570) (-570)
				(-570) (-570) (-570) (-570)
				(-570) (-570) (-570) (-570)
				(-570) (-570) (-570) (-570)
				(-570) (-570) (-570) (-570)
				(-570) (-570) (-570) (-570)
				(-570) (-570) (-570) (-570)
				(-570) (-570) (-570) (-570)
				(-570) (-570) (-570) (-570)
				(-570) (-570) (-570) (-570)
				(-570) (-570) (-570) (-570)
				(-570) (-570) (-570) (-570)
				(-570) (-570) (-570) (-570)
				(-570) (-570) (-570) (-570)
				(-570) (-570) (-570) (-570)
				(-570) (-570) (-570) (-570)
				(-570) (-570) (-570) (-570)
				(-570) (-570) (-570) (-570)
				(-570) (-570) (-570) (-570)
				(-570) (-570) (-570) (-570)
				(-570) (-570) (-570) (-570)
				(-570) (-570) (-570) (-570)
				(-570) (-570) (-570) (-570)
				(-570) (-570) (-570) (-570)
				(-570) (-570) (-570) (-570)
				(-570) (-570) (-570) (-570)
				(-570) (-570) (-570) (-570)
				(-570) (-570) (-570) (-570)
				(-570) (-570) (-570) (-570)
				(-570) (-570) (-570) (-570)
				(-570) (-570) (-570) (-570)
				(-570) (-570) (-570) (-570)
				(-570) (-570) (-570) (-570)
				(-570) (-570) (-570) (-570)
				(-570) (-570) (-570) (-570)
				(-570) (-570) (-570) (-570)
				(-570) (-570) (-570) (-570)
				(-570) (-570) (-570) (-570)
				(-570) (-570) (-570) (-570)
				(-570) (-570) (-570) (-570)
				(-570) (-570) (-570) (-570)
				(-570) (-570) (-570) (-570)
				(-570) (-570) (-570) (-570)
				(-570) (-570) (-570) (-570)>;

			PS_Config_Lmt_PenTipX_FW_Diff_P = <
				870 870 870 870 870 870 870 870 870 870 870 870 870 870 870 870 870 870 870 870 870 870 870 870 870 870 870 870 870 870 870 870
				870 870 870 870 870 870 870 870 870 870 870 870 870 870 870 870 870 870 870 870 870 870 870 870 870 870 870 870 870 870 870 870
				870 870 870 870 870 870 870 870 870 870 870 870 870 870 870 870 870 870 870 870 870 870 870 870 870 870 870 870 870 870 870 870
				870 870 870 870 870 870 870 870 870 870 870 870 870 870 870 870 870 870 870 870 870 870 870 870 870 870 870 870 870 870 870 870
				870 870 870 870 870 870 870 870 870 870 870 870 870 870 870 870 870 870 870 870 870 870 870 870 870 870 870 870 870 870 870 870
				870 870 870 870 870 870 870 870 870 870 870 870 870 870 870 870 870 870 870 870 870 870 870 870 870 870 870 870 870 870 870 870>;

			PS_Config_Lmt_PenTipX_FW_Diff_N = <
				(-870) (-870) (-870) (-870) (-870) (-870) (-870) (-870) (-870) (-870) (-870) (-870) (-870) (-870) (-870) (-870) (-870) (-870) (-870) (-870) (-870) (-870) (-870) (-870) (-870) (-870) (-870) (-870) (-870) (-870) (-870) (-870)
				(-870) (-870) (-870) (-870) (-870) (-870) (-870) (-870) (-870) (-870) (-870) (-870) (-870) (-870) (-870) (-870) (-870) (-870) (-870) (-870) (-870) (-870) (-870) (-870) (-870) (-870) (-870) (-870) (-870) (-870) (-870) (-870)
				(-870) (-870) (-870) (-870) (-870) (-870) (-870) (-870) (-870) (-870) (-870) (-870) (-870) (-870) (-870) (-870) (-870) (-870) (-870) (-870) (-870) (-870) (-870) (-870) (-870) (-870) (-870) (-870) (-870) (-870) (-870) (-870)
				(-870) (-870) (-870) (-870) (-870) (-870) (-870) (-870) (-870) (-870) (-870) (-870) (-870) (-870) (-870) (-870) (-870) (-870) (-870) (-870) (-870) (-870) (-870) (-870) (-870) (-870) (-870) (-870) (-870) (-870) (-870) (-870)
				(-870) (-870) (-870) (-870) (-870) (-870) (-870) (-870) (-870) (-870) (-870) (-870) (-870) (-870) (-870) (-870) (-870) (-870) (-870) (-870) (-870) (-870) (-870) (-870) (-870) (-870) (-870) (-870) (-870) (-870) (-870) (-870)
				(-870) (-870) (-870) (-870) (-870) (-870) (-870) (-870) (-870) (-870) (-870) (-870) (-870) (-870) (-870) (-870) (-870) (-870) (-870) (-870) (-870) (-870) (-870) (-870) (-870) (-870) (-870) (-870) (-870) (-870) (-870) (-870)>;

			PS_Config_Lmt_PenTipY_FW_Diff_P = <
				870 870 870 870
				870 870 870 870
				870 870 870 870
				870 870 870 870
				870 870 870 870
				870 870 870 870
				870 870 870 870
				870 870 870 870
				870 870 870 870
				870 870 870 870
				870 870 870 870
				870 870 870 870
				870 870 870 870
				870 870 870 870
				870 870 870 870
				870 870 870 870
				870 870 870 870
				870 870 870 870
				870 870 870 870
				870 870 870 870
				870 870 870 870
				870 870 870 870
				870 870 870 870
				870 870 870 870
				870 870 870 870
				870 870 870 870
				870 870 870 870
				870 870 870 870
				870 870 870 870
				870 870 870 870
				870 870 870 870
				870 870 870 870
				870 870 870 870
				870 870 870 870
				870 870 870 870
				870 870 870 870
				870 870 870 870
				870 870 870 870
				870 870 870 870
				870 870 870 870
				870 870 870 870
				870 870 870 870
				870 870 870 870
				870 870 870 870
				870 870 870 870
				870 870 870 870
				870 870 870 870
				870 870 870 870
				870 870 870 870
				870 870 870 870>;

			PS_Config_Lmt_PenTipY_FW_Diff_N = <
				(-870) (-870) (-870) (-870)
				(-870) (-870) (-870) (-870)
				(-870) (-870) (-870) (-870)
				(-870) (-870) (-870) (-870)
				(-870) (-870) (-870) (-870)
				(-870) (-870) (-870) (-870)
				(-870) (-870) (-870) (-870)
				(-870) (-870) (-870) (-870)
				(-870) (-870) (-870) (-870)
				(-870) (-870) (-870) (-870)
				(-870) (-870) (-870) (-870)
				(-870) (-870) (-870) (-870)
				(-870) (-870) (-870) (-870)
				(-870) (-870) (-870) (-870)
				(-870) (-870) (-870) (-870)
				(-870) (-870) (-870) (-870)
				(-870) (-870) (-870) (-870)
				(-870) (-870) (-870) (-870)
				(-870) (-870) (-870) (-870)
				(-870) (-870) (-870) (-870)
				(-870) (-870) (-870) (-870)
				(-870) (-870) (-870) (-870)
				(-870) (-870) (-870) (-870)
				(-870) (-870) (-870) (-870)
				(-870) (-870) (-870) (-870)
				(-870) (-870) (-870) (-870)
				(-870) (-870) (-870) (-870)
				(-870) (-870) (-870) (-870)
				(-870) (-870) (-870) (-870)
				(-870) (-870) (-870) (-870)
				(-870) (-870) (-870) (-870)
				(-870) (-870) (-870) (-870)
				(-870) (-870) (-870) (-870)
				(-870) (-870) (-870) (-870)
				(-870) (-870) (-870) (-870)
				(-870) (-870) (-870) (-870)
				(-870) (-870) (-870) (-870)
				(-870) (-870) (-870) (-870)
				(-870) (-870) (-870) (-870)
				(-870) (-870) (-870) (-870)
				(-870) (-870) (-870) (-870)
				(-870) (-870) (-870) (-870)
				(-870) (-870) (-870) (-870)
				(-870) (-870) (-870) (-870)
				(-870) (-870) (-870) (-870)
				(-870) (-870) (-870) (-870)
				(-870) (-870) (-870) (-870)
				(-870) (-870) (-870) (-870)
				(-870) (-870) (-870) (-870)
				(-870) (-870) (-870) (-870)>;

			PS_Config_Lmt_PenRingX_FW_Diff_P = <
				870 870 870 870 870 870 870 870 870 870 870 870 870 870 870 870 870 870 870 870 870 870 870 870 870 870 870 870 870 870 870 870
				870 870 870 870 870 870 870 870 870 870 870 870 870 870 870 870 870 870 870 870 870 870 870 870 870 870 870 870 870 870 870 870
				870 870 870 870 870 870 870 870 870 870 870 870 870 870 870 870 870 870 870 870 870 870 870 870 870 870 870 870 870 870 870 870
				870 870 870 870 870 870 870 870 870 870 870 870 870 870 870 870 870 870 870 870 870 870 870 870 870 870 870 870 870 870 870 870
				870 870 870 870 870 870 870 870 870 870 870 870 870 870 870 870 870 870 870 870 870 870 870 870 870 870 870 870 870 870 870 870
				870 870 870 870 870 870 870 870 870 870 870 870 870 870 870 870 870 870 870 870 870 870 870 870 870 870 870 870 870 870 870 870>;

			PS_Config_Lmt_PenRingX_FW_Diff_N = <
				(-870) (-870) (-870) (-870) (-870) (-870) (-870) (-870) (-870) (-870) (-870) (-870) (-870) (-870) (-870) (-870) (-870) (-870) (-870) (-870) (-870) (-870) (-870) (-870) (-870) (-870) (-870) (-870) (-870) (-870) (-870) (-870)
				(-870) (-870) (-870) (-870) (-870) (-870) (-870) (-870) (-870) (-870) (-870) (-870) (-870) (-870) (-870) (-870) (-870) (-870) (-870) (-870) (-870) (-870) (-870) (-870) (-870) (-870) (-870) (-870) (-870) (-870) (-870) (-870)
				(-870) (-870) (-870) (-870) (-870) (-870) (-870) (-870) (-870) (-870) (-870) (-870) (-870) (-870) (-870) (-870) (-870) (-870) (-870) (-870) (-870) (-870) (-870) (-870) (-870) (-870) (-870) (-870) (-870) (-870) (-870) (-870)
				(-870) (-870) (-870) (-870) (-870) (-870) (-870) (-870) (-870) (-870) (-870) (-870) (-870) (-870) (-870) (-870) (-870) (-870) (-870) (-870) (-870) (-870) (-870) (-870) (-870) (-870) (-870) (-870) (-870) (-870) (-870) (-870)
				(-870) (-870) (-870) (-870) (-870) (-870) (-870) (-870) (-870) (-870) (-870) (-870) (-870) (-870) (-870) (-870) (-870) (-870) (-870) (-870) (-870) (-870) (-870) (-870) (-870) (-870) (-870) (-870) (-870) (-870) (-870) (-870)
				(-870) (-870) (-870) (-870) (-870) (-870) (-870) (-870) (-870) (-870) (-870) (-870) (-870) (-870) (-870) (-870) (-870) (-870) (-870) (-870) (-870) (-870) (-870) (-870) (-870) (-870) (-870) (-870) (-870) (-870) (-870) (-870)>;

			PS_Config_Lmt_PenRingY_FW_Diff_P = <
				870 870 870 870
				870 870 870 870
				870 870 870 870
				870 870 870 870
				870 870 870 870
				870 870 870 870
				870 870 870 870
				870 870 870 870
				870 870 870 870
				870 870 870 870
				870 870 870 870
				870 870 870 870
				870 870 870 870
				870 870 870 870
				870 870 870 870
				870 870 870 870
				870 870 870 870
				870 870 870 870
				870 870 870 870
				870 870 870 870
				870 870 870 870
				870 870 870 870
				870 870 870 870
				870 870 870 870
				870 870 870 870
				870 870 870 870
				870 870 870 870
				870 870 870 870
				870 870 870 870
				870 870 870 870
				870 870 870 870
				870 870 870 870
				870 870 870 870
				870 870 870 870
				870 870 870 870
				870 870 870 870
				870 870 870 870
				870 870 870 870
				870 870 870 870
				870 870 870 870
				870 870 870 870
				870 870 870 870
				870 870 870 870
				870 870 870 870
				870 870 870 870
				870 870 870 870
				870 870 870 870
				870 870 870 870
				870 870 870 870
				870 870 870 870>;

			PS_Config_Lmt_PenRingY_FW_Diff_N = <
				(-870) (-870) (-870) (-870)
				(-870) (-870) (-870) (-870)
				(-870) (-870) (-870) (-870)
				(-870) (-870) (-870) (-870)
				(-870) (-870) (-870) (-870)
				(-870) (-870) (-870) (-870)
				(-870) (-870) (-870) (-870)
				(-870) (-870) (-870) (-870)
				(-870) (-870) (-870) (-870)
				(-870) (-870) (-870) (-870)
				(-870) (-870) (-870) (-870)
				(-870) (-870) (-870) (-870)
				(-870) (-870) (-870) (-870)
				(-870) (-870) (-870) (-870)
				(-870) (-870) (-870) (-870)
				(-870) (-870) (-870) (-870)
				(-870) (-870) (-870) (-870)
				(-870) (-870) (-870) (-870)
				(-870) (-870) (-870) (-870)
				(-870) (-870) (-870) (-870)
				(-870) (-870) (-870) (-870)
				(-870) (-870) (-870) (-870)
				(-870) (-870) (-870) (-870)
				(-870) (-870) (-870) (-870)
				(-870) (-870) (-870) (-870)
				(-870) (-870) (-870) (-870)
				(-870) (-870) (-870) (-870)
				(-870) (-870) (-870) (-870)
				(-870) (-870) (-870) (-870)
				(-870) (-870) (-870) (-870)
				(-870) (-870) (-870) (-870)
				(-870) (-870) (-870) (-870)
				(-870) (-870) (-870) (-870)
				(-870) (-870) (-870) (-870)
				(-870) (-870) (-870) (-870)
				(-870) (-870) (-870) (-870)
				(-870) (-870) (-870) (-870)
				(-870) (-870) (-870) (-870)
				(-870) (-870) (-870) (-870)
				(-870) (-870) (-870) (-870)
				(-870) (-870) (-870) (-870)
				(-870) (-870) (-870) (-870)
				(-870) (-870) (-870) (-870)
				(-870) (-870) (-870) (-870)
				(-870) (-870) (-870) (-870)
				(-870) (-870) (-870) (-870)
				(-870) (-870) (-870) (-870)
				(-870) (-870) (-870) (-870)
				(-870) (-870) (-870) (-870)
				(-870) (-870) (-870) (-870)>;

			PS_Config_Diff_Test_Frame = <50>;
		};
	};
};
